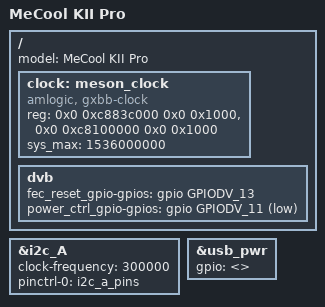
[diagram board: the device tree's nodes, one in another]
// SPDX-License-Identifier: (GPL-3.0+ OR MIT)
/*
 * Author: afl1 <afl2001@gmail.com>
 */

#include "meson-gxbb-p201.dts"
#include "meson-gxl-dvb.dtsi"
/ {
	model = "MeCool KII Pro";

	clock: meson_clock {
		compatible = "amlogic, gxbb-clock";
		reg = <0x0 0xc883c000 0x0 0x1000>,   /* HIU BUS*/
		          <0x0 0xc8100000 0x0 0x1000>;   //AOBUS
		#clock-cells = <1>;
		#reset-cells = <1>;
		sys_max = <1536000000>;
	};
	dvb {
		fec_reset_gpio-gpios = <&gpio GPIODV_13 GPIO_ACTIVE_HIGH>;
		power_ctrl_gpio-gpios = <&gpio GPIODV_11 GPIO_ACTIVE_LOW>;
	};
};

&i2c_A {
	status = "okay";
	clock-frequency = <300000>;
	pinctrl-0 = <&i2c_a_pins>;
	pinctrl-names = "default";
};

&usb_pwr {
		gpio = <>;
};
